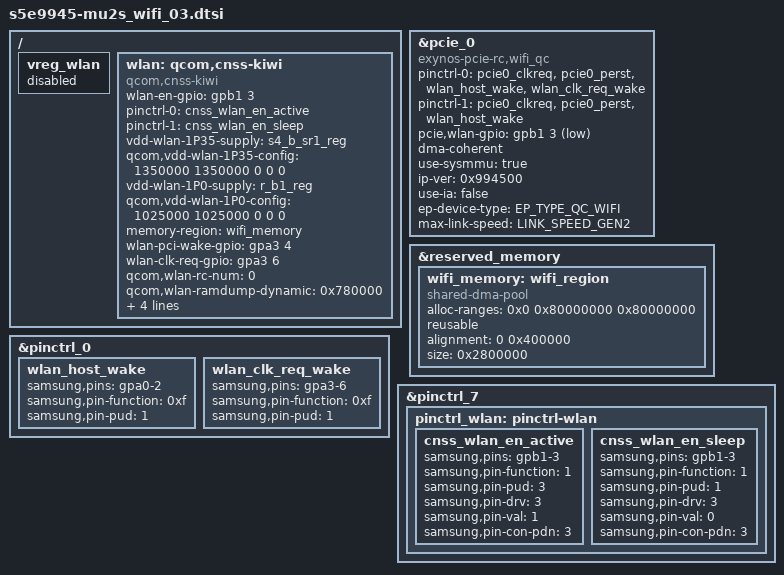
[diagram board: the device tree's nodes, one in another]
/* Qualcomm CNSS KIWI V2 device tree source */

/ {
    fragment@model {
        target-path = "/";
        __overlay__ {
			vreg_wlan: vreg_wlan {
				status = "disabled";
			};
            wlan: qcom,cnss-kiwi {
                compatible = "qcom,cnss-kiwi";
                wlan-en-gpio = <&gpb1 3 0>;
/*                 wlan-host-sol-gpio = <&gpa2 1 0x0>; */
/*                wlan-dev-sol-gpio = <&gpp2 3 0x0>; */
				
                pinctrl-names = "wlan_en_active", "wlan_en_sleep";
                pinctrl-0 = <&cnss_wlan_en_active>;
                pinctrl-1 = <&cnss_wlan_en_sleep>;
/*             wlan,regulator_name = "vreg_wlan"; */
				vdd-wlan-1P35-supply = <&s4_b_sr1_reg>;
				qcom,vdd-wlan-1P35-config = <1350000 1350000 0 0 0>;
				vdd-wlan-1P0-supply = <&r_b1_reg>;
				qcom,vdd-wlan-1P0-config = <1025000 1025000 0 0 0>;
                memory-region = <&wifi_memory>;
                wlan-pci-wake-gpio = <&gpa3 4 0x0>;
                wlan-clk-req-gpio = <&gpa3 6 0x0>;
                qcom,wlan-rc-num = <0>;
                qcom,wlan-ramdump-dynamic = <0x780000>;
                qcom,wlan-cbc-enabled;
                qcom,same-dt-multi-dev;
                qcom,wlan;
                use-pm-domain;
                status = "okay";
            };
        };
    };
};

&pcie_0 {
    compatible = "exynos-pcie-rc,wifi_qc";
    pinctrl-names = "active","idle";
    pinctrl-0 = <&pcie0_clkreq &pcie0_perst &wlan_host_wake &wlan_clk_req_wake>;
    pinctrl-1 = <&pcie0_clkreq &pcie0_perst &wlan_host_wake>;
    pcie,wlan-gpio = <&gpb1 3 0x1>;
    status = "okay";
    dma-coherent;
    use-sysmmu = "true";
    ip-ver = <0x994500>;
    use-ia = "false";
    /* use-msi = "true"; */
    /* ep-device-name = "WIFI"; */
    ep-device-type = <EP_TYPE_QC_WIFI>;
    max-link-speed = <LINK_SPEED_GEN2>;
};

&reserved_memory {
    wifi_memory: wifi_region {
        compatible = "shared-dma-pool";
        alloc-ranges = <0x0 0x80000000 0x80000000>;
        reusable;
        alignment = <0 0x400000>;
        size = <0x2800000>;
    };
};

&pinctrl_0 {
    wlan_host_wake: wlan_host_wake {
        samsung,pins = "gpa0-2";
        samsung,pin-function = <0xf>;
        samsung,pin-pud = <1>;
    };

    wlan_clk_req_wake: wlan_clk_req_wake {
        samsung,pins = "gpa3-6";
        samsung,pin-function = <0xf>;
        samsung,pin-pud = <1>;
    };
};

&pinctrl_7 {
    pinctrl_wlan: pinctrl-wlan {
        cnss_wlan_en_active: cnss_wlan_en_active {
            samsung,pins = "gpb1-3";
            samsung,pin-function = <1>;
            samsung,pin-pud = <3>;
            samsung,pin-drv = <3>;
            samsung,pin-val = <1>;
			samsung,pin-con-pdn = <3>;
        };
        cnss_wlan_en_sleep: cnss_wlan_en_sleep {
            samsung,pins = "gpb1-3";
            samsung,pin-function = <1>;
            samsung,pin-pud = <1>;
            samsung,pin-drv = <3>;
            samsung,pin-val = <0>;
			samsung,pin-con-pdn = <3>;			
        };
    };
};
